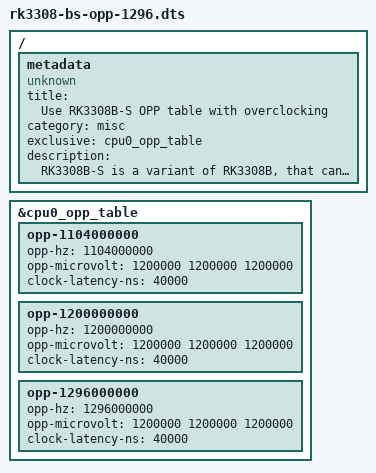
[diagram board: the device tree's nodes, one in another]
// Based on Armbian overlays-11-add-rk3308bs.patch
/dts-v1/;
/plugin/;

#include "rk3308-bs-opp.dtsi"

/ {
	metadata {
		title = "Use RK3308B-S OPP table with overclocking";
		compatible = "unknown";
		category = "misc";
		exclusive = "cpu0_opp_table";
		description = "RK3308B-S is a variant of RK3308B, that can operate at lower voltage.
This overlay additionally adds a 1.3 GHz operating point.
Enable this overlay on regular RK3308 system may render it non-bootable.";
	};
};

&cpu0_opp_table {
	opp-1104000000 {
		opp-hz = /bits/ 64 <1104000000>;
		opp-microvolt = <1200000 1200000 1200000>;
		clock-latency-ns = <40000>;
	};
	//the following are unsupported, overclocked operating points
	opp-1200000000 {
		opp-hz = /bits/ 64 <1200000000>;
		opp-microvolt = <1200000 1200000 1200000>;
		clock-latency-ns = <40000>;
		status = "okay";
	};
	opp-1296000000 {
		opp-hz = /bits/ 64 <1296000000>;
		opp-microvolt = <1200000 1200000 1200000>;
		clock-latency-ns = <40000>;
		status = "okay";
	};
};
